VERSION ""

NS_ :

BS_:

BU_: TleCtBox Control
VAL_TABLE_ WorkModeDataType 1 "DirectrPwmMode" 0 "CurrentMode" ;

BO_ 1371 BMS_55B: 64 BMS
 SG_ BMS_CellUMinGb : 103|16@0+ (0.0010000000,0.0000000000) [0.0000000000|65.5350000000] "V"  GW
 SG_ BMS_CellUMinNrGb : 95|8@0+ (1.0000000000,0.0000000000) [0.0000000000|255.0000000000] ""  GW
 SG_ BMS_BattUMinNrGb : 87|8@0+ (1.0000000000,0.0000000000) [0.0000000000|255.0000000000] ""  GW
 SG_ BMS_CellUMaxGb : 71|16@0+ (0.0010000000,0.0000000000) [0.0000000000|65.5350000000] "V"  GW
 SG_ BMS_CellUMaxNrGb : 63|8@0+ (1.0000000000,0.0000000000) [0.0000000000|255.0000000000] ""  GW
 SG_ BMS_BattUMaxNrGb : 55|8@0+ (1.0000000000,0.0000000000) [0.0000000000|255.0000000000] ""  GW
 SG_ BMS_SnsrTNrTotGb : 39|16@0+ (1.0000000000,0.0000000000) [0.0000000000|65535.0000000000] ""  GW
 SG_ BMS_CellNrTotGb : 23|16@0+ (1.0000000000,0.0000000000) [0.0000000000|65535.0000000000] ""  GW
 SG_ BMS_InsulationRGb : 7|16@0+ (1.0000000000,0.0000000000) [0.0000000000|65535.0000000000] "k��"  GW

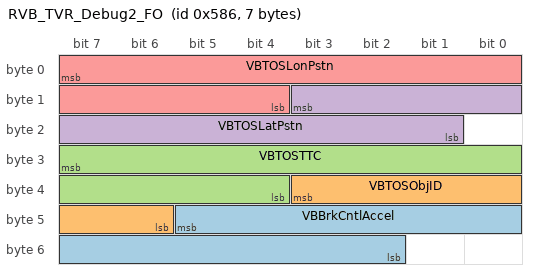
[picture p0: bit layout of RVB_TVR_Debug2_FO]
BO_ 1414 RVB_TVR_Debug2_FO: 7 EOCM_F_FO
 SG_ VBBrkCntlAccel : 45|12@0- (0.01,0) [-20.48|20.47] "m/s^2"  Dummy_FO
 SG_ VBTOSObjID : 35|6@0+ (1,0) [0|63] ""  Dummy_FO
 SG_ VBTOSTTC : 31|12@0+ (0.025,0) [0|102.375] "s"  Dummy_FO
 SG_ VBTOSLatPstn : 11|11@0- (0.125,0) [-128|127.875] "m"  Dummy_FO
 SG_ VBTOSLonPstn : 7|12@0- (0.125,0) [-256|255.875] "m"  Dummy_FO

BO_ 1015 IPK_ODO_Consump: 8 Vector__XXX
 SG_ IPK_EVDTEodometer : 0|12@1+ (1,0) [0|999] "km"  TBOX
